# TM4C129ENCPDT register map
File version: 1.0
CPU: CORTEX_M4 1.0, other endian, MPU, FPU, 3 interrupt priority bits
Registers are 32-bit, read-write, reset 0x0 unless marked. A register's access mark holds for its fields unless they carry their own. Offsets are from the block's base; [hi:lo] are bit positions.

## DES — DES register offsets
Base 0x44038000
0x00 DES_KEY3_L — DES Key 3 LSW for 192-Bit Key
  [31:0] DES_KEY3_L_KEY — [31:0] Key Data
0x04 DES_KEY3_H — DES Key 3 MSW for 192-Bit Key
  [31:0] DES_KEY3_H_KEY — [31:0] Key Data
0x08 DES_KEY2_L — DES Key 2 LSW for 128-Bit Key
  [31:0] DES_KEY2_L_KEY — [31:0] Key Data
0x0C DES_KEY2_H — DES Key 2 MSW for 128-Bit Key
  [31:0] DES_KEY2_H_KEY — [31:0] Key Data
0x10 DES_KEY1_L — DES Key 1 LSW for 64-Bit Key
  [31:0] DES_KEY1_L_KEY — [31:0] Key Data
0x14 DES_KEY1_H — DES Key 1 MSW for 64-Bit Key
  [31:0] DES_KEY1_H_KEY — [31:0] Key Data
0x18 DES_IV_L — DES Initialization Vector
  [31:0] DES_IV_L — [31:0] Initialization vector for CBC, CFB modes (LSW)
0x1C DES_IV_H — DES Initialization Vector
  [31:0] DES_IV_H — [31:0] Initialization vector for CBC, CFB modes (MSW)
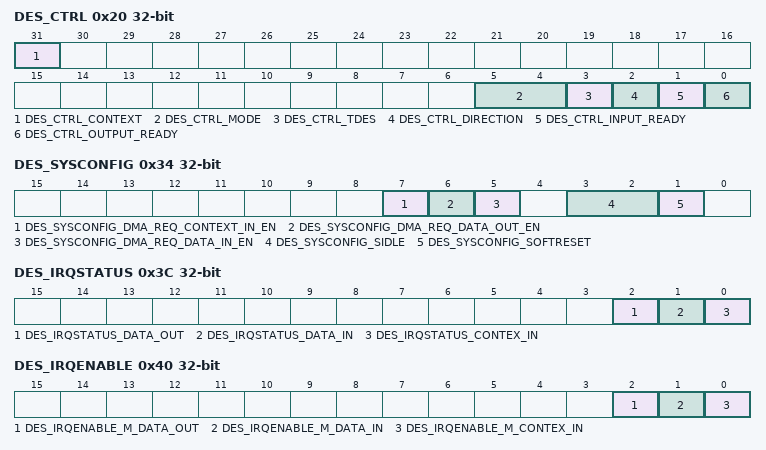
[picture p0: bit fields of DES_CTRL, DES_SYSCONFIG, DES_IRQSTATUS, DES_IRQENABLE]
0x20 DES_CTRL — DES Control
  [31] DES_CTRL_CONTEXT — [31:31] If 1, this read-only status bit indicates that the context data registers can be overwritten and the host is permitted to write the next context
  [5:4] DES_CTRL_MODE — [5:4] Select CBC, ECB or CFB mode0x0: ECB mode0x1: CBC mode0x2: CFB mode0x3: reserved
  [3] DES_CTRL_TDES — [3:3] Select DES or triple DES encryption/decryption
  [2] DES_CTRL_DIRECTION — [2:2] Select encryption/decryption 0x0: decryption is selected0x1: Encryption is selected
  [1] DES_CTRL_INPUT_READY — [1:1] When 1, ready to encrypt/decrypt data
  [0] DES_CTRL_OUTPUT_READY — [0:0] When 1, Data decrypted/encrypted ready
0x24 DES_LENGTH — DES Cryptographic Data Length
  [31:0] DES_LENGTH — [31:0] Cryptographic data length in bytes for all modes
0x28 DES_DATA_L — DES LSW Data RW
  [31:0] DES_DATA_L — [31:0] Data for encryption/decryption, LSW
0x2C DES_DATA_H — DES MSW Data RW
  [31:0] DES_DATA_H — [31:0] Data for encryption/decryption, MSW
0x30 DES_REVISION — DES Revision Number
  [31:0] DES_REVISION — [31:0] Revision number
0x34 DES_SYSCONFIG — DES System Configuration
  [7] DES_SYSCONFIG_DMA_REQ_CONTEXT_IN_EN — [7:7] DMA Request Context In Enable
  [6] DES_SYSCONFIG_DMA_REQ_DATA_OUT_EN — [6:6] DMA Request Data Out Enable
  [5] DES_SYSCONFIG_DMA_REQ_DATA_IN_EN — [5:5] DMA Request Data In Enable
  [3:2] DES_SYSCONFIG_SIDLE — [3:2] Sidle mode
    0=DES_SYSCONFIG_SIDLE_FORCE (Force-idle mode)
  [1] DES_SYSCONFIG_SOFTRESET — [1:1] Soft reset
0x38 DES_SYSSTATUS — DES System Status
  [0] DES_SYSSTATUS_RESETDONE — [0:0] Reset Done
0x3C DES_IRQSTATUS — DES Interrupt Status
  [2] DES_IRQSTATUS_DATA_OUT — [2:2] This bit indicates data output interrupt is active and triggers the interrupt output
  [1] DES_IRQSTATUS_DATA_IN — [1:1] This bit indicates data input interrupt is active and triggers the interrupt output
  [0] DES_IRQSTATUS_CONTEX_IN — [0:0] This bit indicates context interrupt is active and triggers the interrupt output
0x40 DES_IRQENABLE — DES Interrupt Enable
  [2] DES_IRQENABLE_M_DATA_OUT — [2:2] If this bit is set to 1 the data output interrupt is enabled
  [1] DES_IRQENABLE_M_DATA_IN — [1:1] If this bit is set to 1 the data input interrupt is enabled
  [0] DES_IRQENABLE_M_CONTEX_IN — [0:0] If this bit is set to 1 the context interrupt is enabled
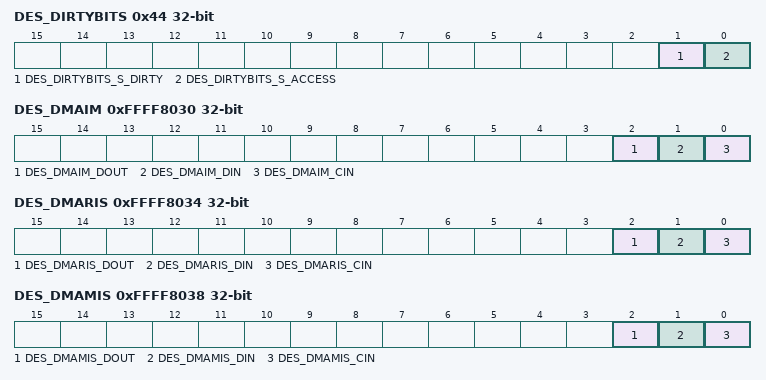
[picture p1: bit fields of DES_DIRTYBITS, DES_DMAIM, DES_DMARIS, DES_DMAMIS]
0x44 DES_DIRTYBITS
  [1] DES_DIRTYBITS_S_DIRTY — [1:1] This bit is set to 1 by the module if any of the DES_* registers is written
  [0] DES_DIRTYBITS_S_ACCESS — [0:0] This bit is set to 1 by the module if any of the DES_* registers is read
0xFFFF8030 DES_DMAIM — DES DMA Interrupt Mask
  [2] DES_DMAIM_DOUT — [2:2] Data Out DMA Done Interrupt Mask
  [1] DES_DMAIM_DIN — [1:1] Data In DMA Done Interrupt Mask
  [0] DES_DMAIM_CIN — [0:0] Context In DMA Done Interrupt Mask
0xFFFF8034 DES_DMARIS — DES DMA Raw Interrupt Status
  [2] DES_DMARIS_DOUT — [2:2] Data Out DMA Done Raw Interrupt Status
  [1] DES_DMARIS_DIN — [1:1] Data In DMA Done Raw Interrupt Status
  [0] DES_DMARIS_CIN — [0:0] Context In DMA Done Raw Interrupt Status
0xFFFF8038 DES_DMAMIS — DES DMA Masked Interrupt Status
  [2] DES_DMAMIS_DOUT — [2:2] Data Out DMA Done Masked Interrupt Status
  [1] DES_DMAMIS_DIN — [1:1] Data In DMA Done Masked Interrupt Status
  [0] DES_DMAMIS_CIN — [0:0] Context In DMA Done Raw Interrupt Status
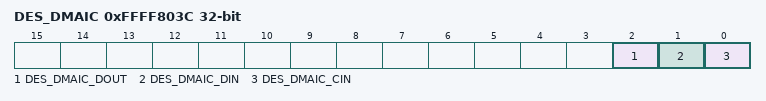
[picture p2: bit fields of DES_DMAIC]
0xFFFF803C DES_DMAIC — DES DMA Interrupt Clear
  [2] DES_DMAIC_DOUT — [2:2] Data Out DMA Done Interrupt Clear
  [1] DES_DMAIC_DIN — [1:1] Data In DMA Done Interrupt Clear
  [0] DES_DMAIC_CIN — [0:0] Context In DMA Done Raw Interrupt Status
